# f1c100s register map
Vendor: Allwinner; File version: 1.0
Registers are 32-bit, read-write, reset 0x0 unless marked. A register's access mark holds for its fields unless they carry their own. Offsets are from the block's base; [hi:lo] are bit positions; {n}, {i} and the like mark numbered series; 'fields as' and 'values as' point back to an identical list.

## DMA — DMA Controller - 4 Normal DMA (NDMA) channels and 4 Dedicated DMA (DDMA) channels
Base 0x01C02000
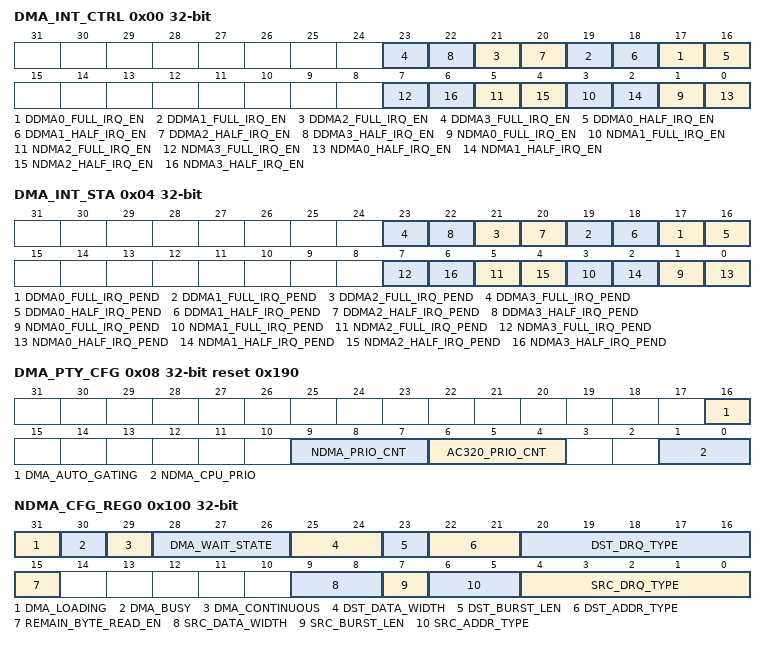
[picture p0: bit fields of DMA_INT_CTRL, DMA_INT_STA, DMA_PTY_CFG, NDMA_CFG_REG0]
0x00 DMA_INT_CTRL — DMA Interrupt Control Register
  [2n+17] DDMA{n}_FULL_IRQ_EN (n=0..3) — Dedicated DMA {n} Full Transfer Interrupt Enable. 0=Disable, 1=Enable
  [2n+16] DDMA{n}_HALF_IRQ_EN (n=0..3) — Dedicated DMA {n} Half Transfer Interrupt Enable. 0=Disable, 1=Enable
  [2n+1] NDMA{n}_FULL_IRQ_EN (n=0..3) — Normal DMA {n} Full Transfer Interrupt Enable. 0=Disable, 1=Enable
  [2n] NDMA{n}_HALF_IRQ_EN (n=0..3) — Normal DMA {n} Half Transfer Interrupt Enable. 0=Disable, 1=Enable
0x04 DMA_INT_STA — DMA Interrupt Status Register (write 1 to clear)
  [2n+17] DDMA{n}_FULL_IRQ_PEND (n=0..3) — Dedicated DMA {n} Full Transfer Interrupt Pending. Write 1 to clear.
  [2n+16] DDMA{n}_HALF_IRQ_PEND (n=0..3) — Dedicated DMA {n} Half Transfer Interrupt Pending. Write 1 to clear.
  [2n+1] NDMA{n}_FULL_IRQ_PEND (n=0..3) — Normal DMA {n} Full Transfer Interrupt Pending. Write 1 to clear.
  [2n] NDMA{n}_HALF_IRQ_PEND (n=0..3) — Normal DMA {n} Half Transfer Interrupt Pending. Write 1 to clear.
0x08 DMA_PTY_CFG reset 0x190 — DMA Priority Configure Register
  [16] DMA_AUTO_GATING — DMA Auto Clock Gating. 0=Enable auto gating, 1=Disable auto gating. Set to 1 for continuous mode.
  [9:7] NDMA_PRIO_CNT — NDMA Priority Counter. NDMA can continuously access AHB for N+1 times.
  [6:4] AC320_PRIO_CNT — AC320 Priority Counter. AC320 can continuously access AHB for N+1 times.
  [1:0] NDMA_CPU_PRIO — NDMA/CPU Priority. 00=CPU>NDMA, 01=NDMA>CPU
0x100 NDMA_CFG_REG0 — Normal DMA Channel 0 Configure Register
  [31] DMA_LOADING — DMA Loading. Set 1 to start, auto-cleared when finished. Set 0 to reset channel.
  [30] DMA_BUSY ro — DMA Busy Status. 0=Idle, 1=Busy
  [29] DMA_CONTINUOUS — DMA Continuous Mode Enable. 0=Disable, 1=Enable
  [28:26] DMA_WAIT_STATE — DMA Wait State. 0=1, 1=2, 2=4, 3=8, 4=16, 5=32, 6=64, 7=128
  [25:24] DST_DATA_WIDTH — Destination Data Width. 00=8-bit, 01=16-bit, 10=32-bit
  [23] DST_BURST_LEN — Destination Burst Length. 0=1, 1=4
  [22:21] DST_ADDR_TYPE — Destination Address Type. 00=Linear, 01=IO
  [20:16] DST_DRQ_TYPE — Destination DRQ Type. 0x01=OWA_TX, 0x04=SPI0_TX, 0x05=SPI1_TX, 0x08=UART0_TX, 0x09=UART1_TX, 0x0A=UART2_TX, 0x0C=AudioCodec_DAC, 0x0E=DAUDIO, 0x10=SRAM, 0x11=SDRAM, 0x14=USB, 0x15=USB_EP1, 0x16=USB_EP2, 0x17=USB_EP3
  [15] REMAIN_BYTE_READ_EN — Remain byte counter read enable. If set, remain byte counter can be read from NDMA_BYTE_CNT_REG.
  [9:8] SRC_DATA_WIDTH — Source Data Width. 00=8-bit, 01=16-bit, 10=32-bit
  [7] SRC_BURST_LEN — Source Burst Length. 0=1, 1=4
  [6:5] SRC_ADDR_TYPE — Source Address Type. 00=Linear, 01=IO
  [4:0] SRC_DRQ_TYPE — Source DRQ Type. 0x00=IR_RX, 0x04=SPI0_RX, 0x05=SPI1_RX, 0x08=UART0_RX, 0x09=UART1_RX, 0x0A=UART2_RX, 0x0C=AudioCodec, 0x0D=TP_ADC, 0x0E=DAUDIO, 0x10=SRAM, 0x11=SDRAM, 0x14=USB, 0x15=USB_EP1, 0x16=USB_EP2, 0x17=USB_EP3
{0x104+0x20*i} NDMA_SRC_ADR_REG{i} (i=0..3) — Normal DMA Channel {i} Source Address Register
  [31:0] SRC_ADDR — Normal DMA Source Address
{0x108+0x20*i} NDMA_DES_ADR_REG{i} (i=0..3) — Normal DMA Channel {i} Destination Address Register
  [31:0] DES_ADDR — Normal DMA Destination Address
0x10C NDMA_BYTE_CNT_REG0 — Normal DMA Channel 0 Byte Counter Register (max 128K)
  [17:0] BYTE_CNT — Normal DMA Byte Counter. 0=no transfer. Max 128K.
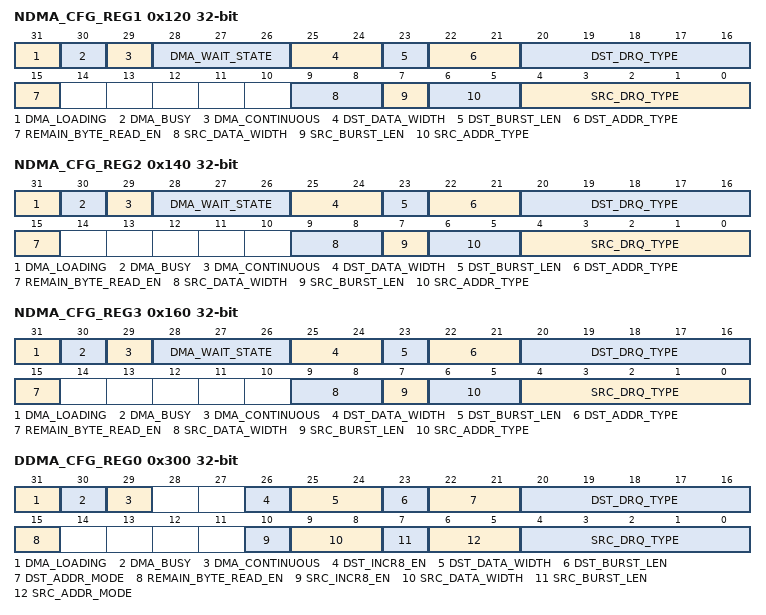
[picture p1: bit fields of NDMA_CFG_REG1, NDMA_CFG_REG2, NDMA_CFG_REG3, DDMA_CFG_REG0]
0x120 NDMA_CFG_REG1 — Normal DMA Channel 1 Configure Register
  [31] DMA_LOADING — DMA Loading. Set 1 to start, auto-cleared when finished.
  [30] DMA_BUSY ro — DMA Busy Status. 0=Idle, 1=Busy
  [29] DMA_CONTINUOUS — DMA Continuous Mode Enable. 0=Disable, 1=Enable
  [28:26] DMA_WAIT_STATE
  [25:24] DST_DATA_WIDTH — Destination Data Width. 00=8-bit, 01=16-bit, 10=32-bit
  [23] DST_BURST_LEN — Destination Burst Length. 0=1, 1=4
  [22:21] DST_ADDR_TYPE — Destination Address Type. 00=Linear, 01=IO
  [20:16] DST_DRQ_TYPE — Destination DRQ Type
  [15] REMAIN_BYTE_READ_EN — Remain byte counter read enable
  [9:8] SRC_DATA_WIDTH — Source Data Width. 00=8-bit, 01=16-bit, 10=32-bit
  [7] SRC_BURST_LEN — Source Burst Length. 0=1, 1=4
  [6:5] SRC_ADDR_TYPE — Source Address Type. 00=Linear, 01=IO
  [4:0] SRC_DRQ_TYPE — Source DRQ Type
{0x10C+0x20*i} NDMA_BYTE_CNT_REG{i} (i=1..3) — Normal DMA Channel {i} Byte Counter Register
  [17:0] BYTE_CNT — Normal DMA Byte Counter
0x140 NDMA_CFG_REG2 — Normal DMA Channel 2 Configure Register
  [31] DMA_LOADING
  [30] DMA_BUSY ro — DMA Busy Status
  [29] DMA_CONTINUOUS — DMA Continuous Mode Enable
  [28:26] DMA_WAIT_STATE
  [25:24] DST_DATA_WIDTH — Destination Data Width
  [23] DST_BURST_LEN — Destination Burst Length
  [22:21] DST_ADDR_TYPE — Destination Address Type
  [20:16] DST_DRQ_TYPE — Destination DRQ Type
  [15] REMAIN_BYTE_READ_EN — Remain byte counter read enable
  [9:8] SRC_DATA_WIDTH — Source Data Width
  [7] SRC_BURST_LEN — Source Burst Length
  [6:5] SRC_ADDR_TYPE — Source Address Type
  [4:0] SRC_DRQ_TYPE — Source DRQ Type
0x160 NDMA_CFG_REG3 — Normal DMA Channel 3 Configure Register
  fields as NDMA_CFG_REG2
0x300 DDMA_CFG_REG0 — Dedicated DMA Channel 0 Configure Register
  [31] DMA_LOADING — DMA Loading. Set 1 to start, auto-cleared when finished. Set 0 to stop and reset state machine.
  [30] DMA_BUSY ro — DMA Busy Status. 0=Idle, 1=Busy
  [29] DMA_CONTINUOUS — DMA Continuous Mode Enable. 0=Disable, 1=Enable
  [26] DST_INCR8_EN — Destination INCR8 enable (only valid for DDMA3). 0=Single/INCR4, 1=INCR8
  [25:24] DST_DATA_WIDTH — Destination Data Width. 00=8-bit, 01=16-bit, 10=32-bit
  [23] DST_BURST_LEN — Destination Burst Length. 0=1, 1=4
  [22:21] DST_ADDR_MODE — Destination Address Mode. 00=Linear, 01=IO
  [20:16] DST_DRQ_TYPE — Destination DRQ Type. 0x0=SRAM, 0x1=SDRAM, 0x2=LCDC, 0x4=USB, 0x9=AHB_Memory
  [15] REMAIN_BYTE_READ_EN — Remain byte counter read enable
  [10] SRC_INCR8_EN — Source INCR8 enable (only valid for DDMA3). 0=Single/INCR4, 1=INCR8
  [9:8] SRC_DATA_WIDTH — Source Data Width. 00=8-bit, 01=16-bit, 10=32-bit
  [7] SRC_BURST_LEN — Source Burst Length. 0=1, 1=4
  [6:5] SRC_ADDR_MODE — Source Address Mode. 00=Linear, 01=IO
  [4:0] SRC_DRQ_TYPE — Source DRQ Type. 0x0=SRAM, 0x1=SDRAM, 0x4=USB, 0x9=AHB_Memory
{0x304+0x20*i} DDMA_SRC_ADR_REG{i} (i=0..3) — Dedicated DMA Channel {i} Source Address Register
  [31:0] SRC_ADDR — Dedicated DMA Source Start Address
{0x308+0x20*i} DDMA_DES_ADR_REG{i} (i=0..3) — Dedicated DMA Channel {i} Destination Address Register
  [31:0] DES_ADDR — Dedicated DMA Destination Start Address
0x30C DDMA_BYTE_CNT_REG0 — Dedicated DMA Channel 0 Byte Counter Register (max 0x1000000)
  [24:0] BYTE_CNT — Dedicated DMA Byte Counter. 0=no transfer. Max 0x1000000.
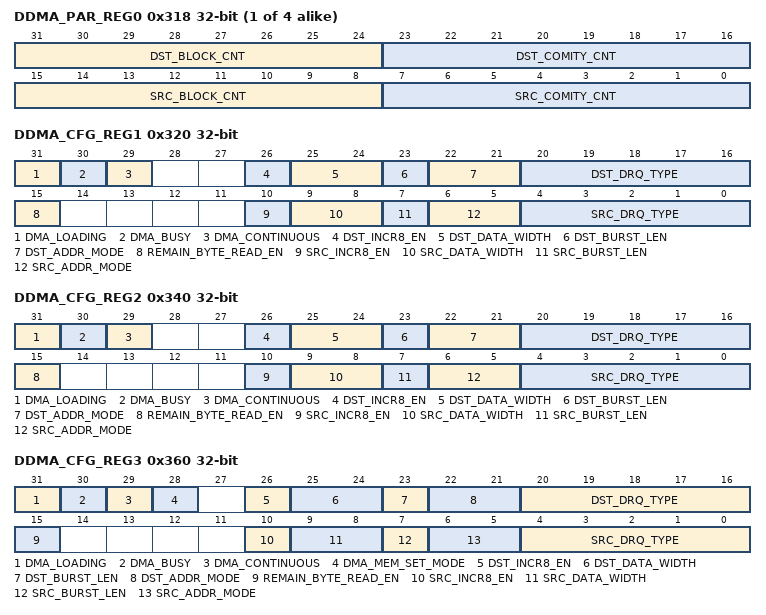
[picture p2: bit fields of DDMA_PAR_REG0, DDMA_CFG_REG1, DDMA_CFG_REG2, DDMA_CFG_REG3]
{0x318+0x20*i} DDMA_PAR_REG{i} (i=0..3) — Dedicated DMA Channel {i} Parameter Register
  [31:24] DST_BLOCK_CNT — Destination Block Counter (value = N+1)
  [23:16] DST_COMITY_CNT — Destination Comity Counter (value = N+1)
  [15:8] SRC_BLOCK_CNT — Source Block Counter (value = N+1)
  [7:0] SRC_COMITY_CNT — Source Comity Counter (value = N+1)
0x320 DDMA_CFG_REG1 — Dedicated DMA Channel 1 Configure Register
  [31] DMA_LOADING
  [30] DMA_BUSY ro — DMA Busy Status
  [29] DMA_CONTINUOUS — DMA Continuous Mode Enable
  [26] DST_INCR8_EN — Destination INCR8 enable
  [25:24] DST_DATA_WIDTH — Destination Data Width
  [23] DST_BURST_LEN — Destination Burst Length
  [22:21] DST_ADDR_MODE — Destination Address Mode
  [20:16] DST_DRQ_TYPE — Destination DRQ Type
  [15] REMAIN_BYTE_READ_EN — Remain byte counter read enable
  [10] SRC_INCR8_EN — Source INCR8 enable
  [9:8] SRC_DATA_WIDTH — Source Data Width
  [7] SRC_BURST_LEN — Source Burst Length
  [6:5] SRC_ADDR_MODE — Source Address Mode
  [4:0] SRC_DRQ_TYPE — Source DRQ Type
{0x30C+0x20*i} DDMA_BYTE_CNT_REG{i} (i=1..3) — Dedicated DMA Channel {i} Byte Counter Register
  [24:0] BYTE_CNT — Dedicated DMA Byte Counter
0x340 DDMA_CFG_REG2 — Dedicated DMA Channel 2 Configure Register
  fields as DDMA_CFG_REG1
0x360 DDMA_CFG_REG3 — Dedicated DMA Channel 3 Configure Register (supports memory set mode, INCR8)
  [31] DMA_LOADING
  [30] DMA_BUSY ro — DMA Busy Status
  [29] DMA_CONTINUOUS — DMA Continuous Mode Enable
  [28] DMA_MEM_SET_MODE — Memory set mode enable. 0=Disable, 1=Move data from DDMA_GEN_DATA to destination. Source config (bit10-0) invalid when set.
  [26] DST_INCR8_EN — Destination INCR8 enable. 0=Single/INCR4, 1=INCR8
  [25:24] DST_DATA_WIDTH — Destination Data Width
  [23] DST_BURST_LEN — Destination Burst Length
  [22:21] DST_ADDR_MODE — Destination Address Mode
  [20:16] DST_DRQ_TYPE — Destination DRQ Type
  [15] REMAIN_BYTE_READ_EN — Remain byte counter read enable
  [10] SRC_INCR8_EN — Source INCR8 enable. 0=Single/INCR4, 1=INCR8
  [9:8] SRC_DATA_WIDTH — Source Data Width
  [7] SRC_BURST_LEN — Source Burst Length
  [6:5] SRC_ADDR_MODE — Source Address Mode
  [4:0] SRC_DRQ_TYPE — Source DRQ Type
0x37C DDMA_GEN_DATA — Dedicated DMA General Data Register (only valid for DDMA3, used with memory set mode)
  [31:0] GEN_DATA — Dedicated DMA general data (used as source in memory set mode)
